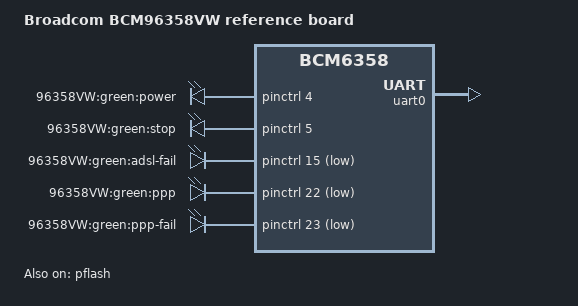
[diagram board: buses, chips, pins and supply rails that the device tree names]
/dts-v1/;

#include "bcm6358.dtsi"

#include <dt-bindings/input/input.h>

/ {
	model = "Broadcom BCM96358VW reference board";
	compatible = "brcm,bcm96358vw", "brcm,bcm6358";

	chosen {
		bootargs = "rootfstype=squashfs,jffs2 noinitrd console=ttyS0,115200";
		stdout-path = "serial0:115200n8";
	};

	gpio-leds {
		compatible = "gpio-leds";

		power_green {
			label = "96358VW:green:power";
			gpios = <&pinctrl 4 0>;
			default-state = "on";
		};
		stop_green {
			label = "96358VW:green:stop";
			gpios = <&pinctrl 5 0>;
		};
		adsl_fail_green {
			label = "96358VW:green:adsl-fail";
			gpios = <&pinctrl 15 1>;
		};
		ppp_green {
			label = "96358VW:green:ppp";
			gpios = <&pinctrl 22 1>;
		};
		ppp_fail_green {
			label = "96358VW:green:ppp-fail";
			gpios = <&pinctrl 23 1>;
		};
	};
};

&pflash {
	status = "ok";

	partitions {
		compatible = "brcm,bcm963xx-cfe-nor-partitions";
	};
};

&uart0 {
	status = "ok";
};
